# EVE2 register map
Vendor: Texas Instruments
Peripheral module from a debugger description file (folder DRA75x_DRA74x).
Registers are 32-bit, read-write, reset 0x0 unless marked. A register's access mark holds for its fields unless they carry their own. Offsets are as the file gives them; lines under a group give offsets from that group; [hi:lo] are bit positions; {n}, {i} and the like mark numbered series; 'fields as' and 'values as' point back to an identical list; <NAME> marks a mode.

## EVE2
0x80000 EVE_REVISION ro
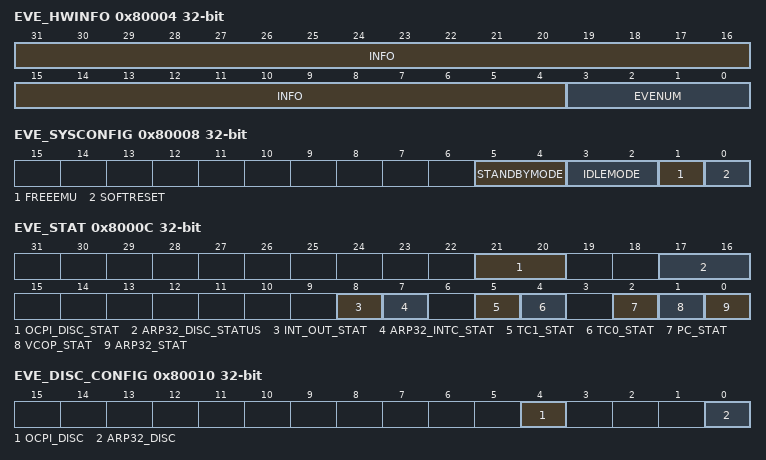
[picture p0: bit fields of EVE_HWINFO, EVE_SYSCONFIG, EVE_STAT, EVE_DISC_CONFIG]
0x80004 EVE_HWINFO ro
  [31:4] INFO — 0x0: No configurable options in EVE
  [3:0] EVENUM — EVE instance number set by eve_num inputs. In a multi-EVE system must be set to unique/incrementing values for each EVE.
0x80008 EVE_SYSCONFIG access per field
  [5:4] STANDBYMODE rw — 00: Force-Standby mode: This mode is a backup mode intended to be used only if the smart-idle mode is bugged. When in this mode / the SAF asserts with minimal hardware condition the status saying :I am in standby:. It is the responsibility of the software to ensure that the SAF is in a correct quiet state before programming this mode. Additionally when in this mode / the SAF is not allowed to generate wakeup reques . 01: No-Standby: This mode is a backup mode intended to be used only if the smart-idle mode is bugged. When in this mode / the SAF never asserts the status declaring that the system is in standby. 10: Smart-Standby: default. EVE generates the standby status based upon all hardware internal status / namely after having performed all hardware operations necessary to be in a correct quiet state. Additionally when in this mode / the SAF is not allowed to generate wakeup request. 11: Smart-Standby-Wkup: Same as Smart-Standby. (EVE generates the standby status based upon all hardware internal status / namely after having performed all hardware operations necessary to be in a correct quiet state ). . Additionally when in this mode / the SAF is allowed to generate wakeup request
  [3:2] IDLEMODE rw — 00: Force-idle: This mode is a backup mode intended to be used only if the smart-idle mode is bugged. When in this mode the IAF acknowledges a request to go idle from the power manager with minimal hardware condition. It is the responsibility of the software to ensure that the IAF are in a correct quiet state before requesting a force-idle transition. Additionaly when in this mode the IAF is not allowed to generate any wakeup request. 01: No-idle: When in this mode the IAF disregards any request to go idle from the power manager. 10: Smart-idle: default mode. default. When in this mode / the IAF acknowledges a request to go idle from the power manager after having performed all hardware operations necessary to be in a correct quiet state. Additionally when in this mode / the IAF is not allowed to generate any wakeup reques 11: SmartIdleWkup : When in this mode / the IAF acknowledges a request to go idle from the power manager after having performed all hardware operations necessary for the IAF to be in a correct quiet state. Additionally when in this mode / the IAF is allowed to generate wakeup request
  [1] FREEEMU ro — Resered. Note that SCTM has free control bit to define the timer operation during ARP32 debug halt mode
  [0] SOFTRESET ro — Reserved
0x8000C EVE_STAT ro — Added missing bit-field descriptions and settings to EVE_STAT register. See delta between vAB and vAC for more details
  [21:20] OCPI_DISC_STAT — OCP Initiator(s) Disconnect status2:
    2=One or both initiators are active, no request to disconnect is pending; 1=One or both initiators are attempting to disconnect; 0=EVEs_OCP_initiators_are_disconnected
  [17:16] ARP32_DISC_STATUS — ARP32 Program/Data Bus Disconnect Status 2:
    2=ARP32_2 (ARP32 program and data busses are active, no request to disconnect is pending); 1=ARP32_1 (ARP32 program and data buses are attempting to disconnect); 0=ARP32_0 (ARP32 program and data buses are disconnected)
  [8] INT_OUT_STAT — Interrupt Output status:
    0=No_edabled_interrupts_pending; 1=Active (at least one enabled interrupt source is pending in the output reducer)
  [7] ARP32_INTC_STAT — Interrupt Controller Status:
    0=No_enabled_interrupts_pending; 1=ARP32_1 (Active (at least one enabled interrupt source is pending in the ARP32 interrupt controller))
  [5] TC1_STAT — Transfer Controller1 Status:
    0=Idle; 1=Active
  [4] TC0_STAT — Transfer Controller0 Status:
    0=Idle; 1=Active
  [2] PC_STAT — Program Cache Status:
    0=Idle; 1=CPU_1 (Active (Program cache is either performing prefetch/preload/invalidation, or is servicing a CPU program fetch request (hit or miss)).)
  [1] VCOP_STAT — VCOP Status :
    0=Idle; 1=VCOP_OCP_1 (Active (Program execution in progress. Based on inverse of vcop_done. Does not account for activity on VCOP OCP debug interface))
  [0] ARP32_STAT — Program Cache Status:
    0=Idle; 1=Active (based on inverse of arp32_stanby)
0x80010 EVE_DISC_CONFIG access per field — Color 0 noise threshold
  [4] OCPI_DISC rw — OCP Initiator Disconnect request:
    1=OCP_1 (request for OCP initiator to disconnect and mask write byte enable signals. Writing 0 has no effect); 0=OCPI_DISC_0_r (Disconnect not in progress of has completed. Read 1: Disconnect request in progress.)
  [0] ARP32_DISC rw — ARP32 Initiator Disconnect request.
    1=ARP32_1 (Request for ARP32 program and data buses to disconnect and mask write byte enable signals. Writing 0 has no effect.); 1=ARP32_DISC_1_r (disconnect request in progress. Read 0: disconnect not in progress or has completed.)
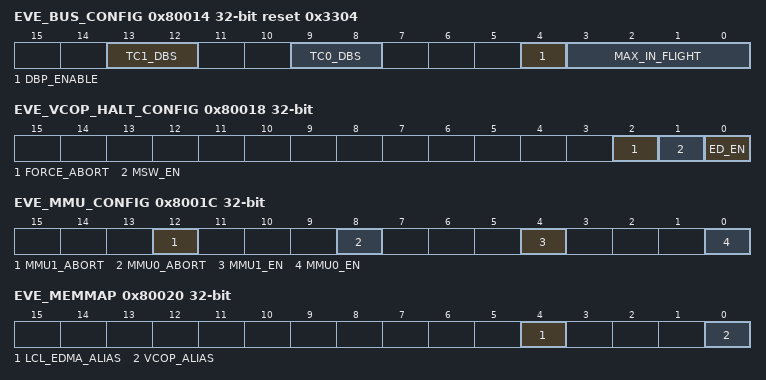
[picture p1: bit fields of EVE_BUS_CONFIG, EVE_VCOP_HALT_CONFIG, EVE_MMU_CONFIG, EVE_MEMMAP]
0x80014 EVE_BUS_CONFIG access per field reset 0x3304 — Color 0 noise threshold
  [13:12] TC1_DBS rw — TC1 default burst size. 00: 16 byte, 01: 32 byte, 10: 64 byte, 11: 128 byte (recommended)
  [9:8] TC0_DBS rw — TC0 default burst size. 00: 16 byte, 01: 32 byte, 10: 64 byte, 11: 128 byte (recommended)
  [4] DBP_ENABLE rw — Program Cache Demand Based Prefetch enable:
    0=DBP_disabled; 1=DBP_enabled
  [3:0] MAX_IN_FLIGHT rw — Defines maximum number of OCP requests in flight. Can be reduced to limit the peak bandwidth for software direct preload, which in turn may provide advantage to other EVE level (e.g. EDMA) or system-level initiators. 0: Reserved. 1: 1 request in flight allowed. 2: 2 requests in flight allowed.. F: 15 requests in flight allowed.
0x80018 EVE_VCOP_HALT_CONFIG access per field
  [2] FORCE_ABORT rw — VCOP Force Abort Write: Read always returns 0sWrite 0 has no effect. .
    1=VCOP_1 (issues force_abort command to VCOP (through pulse on vcop force abort input)
  [1] MSW_EN rw — VCOP Memory Seitch Error Halt Enable:
    0=Disabled; 1=VCOP_VCOP_1 (Enabled. VCOP halts on VCOP initiated memory swithc error)
  [0] ED_EN rw — VCOP Parity Error Detect Halt Enable:
    0=Disabled; 1=VCOP_VCOP_1 (Enabled. VCOP halts on VCOP initiated parity error.)
0x8001C EVE_MMU_CONFIG access per field
  [12] MMU1_ABORT rw — Causes the MMU to abort the current operation in case of lockup
  [8] MMU0_ABORT rw — Causes the MMU to abort the current operation in case of lockup
  [4] MMU1_EN rw — Clearing this bit disables MMU table lookup and causes accesses to use the non-translated address. This bit defaults to enabled but an identical bit within an MMU configuration register defaults to disabled and must be set after the page tables are programmed for MMU operation
  [0] MMU0_EN rw — Clearing this bit disables MMU table lookup and causes accesses to use the non-translated address. This bit defaults to enabled but an identical bit within an MMU configuration register defaults to disabled and must be set after the page tables are programmed for MMU operation
0x80020 EVE_MEMMAP access per field
  [4] LCL_EDMA_ALIAS rw — 0: Local EDMA views full memory map
    1=VCOP_VCOP_IBUFLA_IBUFLB_IBUFHA_IBUFHB_IBUFLA_IBUFLB_IBUFHA_IBUFHB_1 (VCOP vies aliased memory map. In this mode VCOP views IBUFLA and IBUFLB at the same address and views IBUFHA and IBUFHB at the same address. In this mode only one of IBUFLA or IBUFLB and IBUFHA or IBUFHB can be owned by the system.Refer to Error: Reference source not found for full truth table. Software must poll for updated value to ensure mode change has taken effect.)
  [0] VCOP_ALIAS rw — 0: VCOP views full memory map
    1=VCOP_VCOP_IBUFLA_IBUFLB_IBUFHA_IBUFHB_IBUFLA_IBUFLB_VCOP;_IBUFHA_IBUFHB_VCOP._1 (VCOP views Aliased memory map. In this mode / VCOP views IBUFLA and IBUFLB at the same address / and views IBUFHA and IBUFHB at the same address. In this mode / only one of IBUFLA or IBUFLB can be :owned: by VCOP; and only one of IBUFHA or IBUFHB can be :owned: by VCOP. Refer to Error: Reference source not found for full truth table. Software must poll for updated value to ensure mode change has taken effect)
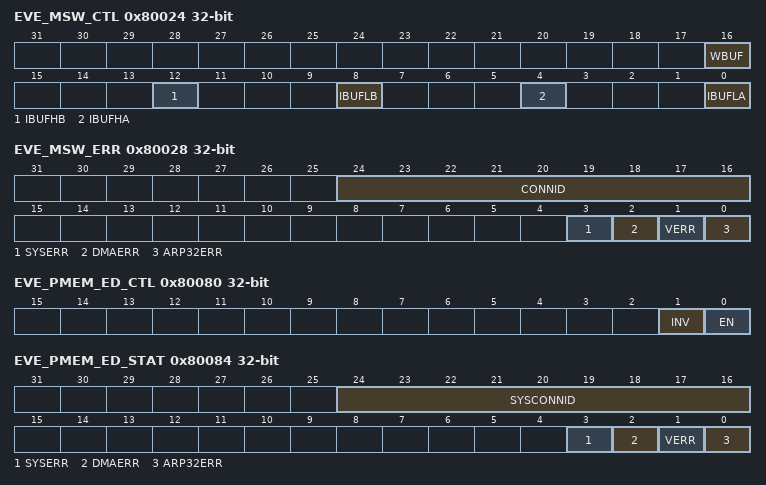
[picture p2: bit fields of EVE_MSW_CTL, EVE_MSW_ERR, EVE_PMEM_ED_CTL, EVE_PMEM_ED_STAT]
0x80024 EVE_MSW_CTL access per field — Memory switch control register
  [all] fields
    0=System_owned; 1=VCOP_owned
  [16] WBUF rw — Working buffer onwership. Value can be modified through direct writes to the memory mapped register address or through ARP32 executing custom instruction __SwitchBuffer(ucst20).
  [12] IBUFHB rw — Image buffer high B ownership. Value can be modified through direct writes to the memory mapped register address or through ARP32 executing custom instruction __SwitchBuffer(ucst20).:
  [8] IBUFLB rw — Image buffer low B ownership. Value can be modified through direct writes to the memory mapped register address or through ARP32 executing custom instruction __SwitchBuffer(ucst20).:
  [4] IBUFHA rw — Image buffer high A ownership. Value can be modified through direct writes to the memory mapped register address or through ARP32 executing custom instruction __SwitchBuffer(ucst20).:
  [0] IBUFLA rw — Image buffer low A ownership. Value can be modified through direct writes to the memory mapped register address or through ARP32 executing custom instruction __SwitchBuffer(ucst20).:
0x80028 EVE_MSW_ERR access per field — Memory Switch Error register
  [24:16] CONNID ro — Reads: OCP CONNID value for OCP request that results in buffer ownership error. CONNID[8] = 0 indicates system initiated request. CONNID[8] = 1 indicates internally initiated request. Valid only when SYSERR is set to 1 otherwise returns 0x0. Undefined when no error status bits are set. CONNID = 0x000 through 0x0FF / system initiator CONNID = 0x100 / ARP32 initiated error CONNID = 0x101 / VCOP initiated error CONNID = 0x102 / EDMA TC0 initiated error CONNID = 0x103 / EDMA TC1 initiated error. Cleared through write :1: to ERR bit field
  [3] SYSERR wo — 0 - System initiated buffer ownership error not recorded 1 - System initiated buffer ownership error detected/recorded. Write 1 to clear.
  [2] DMAERR wo — 0 : EDMA initiated buffer ownership error not recorded 1 : EDMA buffer ownership error detected/recorded Write 1 to clear.
  [1] VERR wo — 0 : VCOP initiated buffer ownership error not recorded 1 : VCOP initiated buffer ownership error detected/recorded Write 1 to clear.
  [0] ARP32ERR wo — 0 : ARP32 initiated buffer ownership error not recorded 1 : ARP32 initiated buffer ownership error detected/recorded Write 1 to clear.
0x8002C EVE_MSW_ERRADDR ro — Memory switch error address register
  [31:0] ADDR — Physical Address (i.e. / not aliased address) of memory switch error. For VCOP accesses / indicates 32-B aligned address. For EDMA or System accesses / indicates 16-B aligned access. For ARP32 / indicates 4-B aligned address. Value is undefined when no ERR bits set.
0x80040 EVE_PC_INV access per field — Invalidate all register
  [0] I rw — Invalidate all:Read: 0 : Invalidate operation complete / or not in progress 1 : Invalidate operation still in progress .
    0=I_0_w (no effet. Write 1: initiate invalidate all command)
0x80050 EVE_PC_IBAR — Invalidate Base Address register
  [31:0] ADDR — Invalidate Base Address register. Defines system byte address base to be invalidated from L1P. The entire range to be invalidated is (loosely speaking) from the base address to the base address + byte count. The actual range is inclusive of cache line (32-B aligned) addresses containing the start address and end address
0x80054 EVE_PC_IBC access per field — Invalidate byte count register
  [15:0] BC rw — Invalidate Byte Count register. Defines number of bytes relative to Invalidate Base Address (IBAR.ADDR) to be invalidated from L1P. Maximum of 32k (0x8000). Reads return 0x0 when invalidate range operation is complete.
0x80058 EVE_PC_ISAR — Invalidate single address register
  [31:0] ADDR — Invalidate Single Address register. Defines system byte address (1 line only) to be invalidated from L1P. Reads return 0x0 when the invalidate operation is complete.
0x8005C EVE_PC_ISAR_DONE ro — Invalidate single address done register
  [0] DONE — Reads return 0x1 when the invalidate operation is complete. Cleared on the next write to theEVE_PC_ISAR register
0x80060 EVE_PC_PBAR — Program cache preload base address register
  [31:0] ADDR — Preload Base Address register. Defines system byte address base to be Preloaded into L1P. The entire range to be Preloaded is (loosely speaking) from the base address to the base address + byte count. The actual range is inclusive of cache line (32-B aligned) addresses containing the start address and end address
0x80064 EVE_PC_PBC access per field
  [15:0] BC rw — Preload Byte Count register. Defines number of bytes relative to Preload Base Address (PBAR.ADDR) to be Preloaded into L1P. Maximum of 32k (0x8000). Reads return 0x0 when Preload range operation is complete
0x80080 EVE_PMEM_ED_CTL access per field — Program Memory Error Detection Control register
  [1] INV rw — Read 0: Error detection logic is not inverted. Read 1: Error detection logic is inverted. Writes to memory set parity as normal. Reds from meory return inverse of parity bit.Write 0 to clear, write 1 to set. Must be set when EN is set .
  [0] EN rw — Error detection logic enable. Writes update parity, reads check parity
    0=Disabled; 1=Enabled
0x80084 EVE_PMEM_ED_STAT access per field — Error detection status register
  [24:16] SYSCONNID rw — Reads: OCP CONNID value for OCP request that results in buffer ownership error. CONNID[8] = 0 indicates system initiated request. CONNID[8] = 1 indicates internally initiated request. Valid only when SYSERR is set to 1 otherwise returns 0x0. CONNID = 0x000 through 0x0FF / system initiator CONNID = 0x100 / ARP32 initiated error CONNID = 0x101 / VCOP initiated error CONNID = 0x102 / EDMA TC0 initiated error CONNID = 0x103 / EDMA TC1 initiated error. Cleared through write :1: to *ERR bit field.
  [3] SYSERR rw — 0 - System initiated parity error not recorded 1 - System initiated parity error detected/recorded. Write 1 to clear.
  [2] DMAERR rw — 0 : EDMA initiated parity error not recorded 1 : EDMA parity error detected/recorded Write 1 to clear.
  [1] VERR rw — 0 : VCOP initiated parity error not recorded 1 : VCOP initiated parity error detected/recorded Write 1 to clear.
  [0] ARP32ERR rw — 0 : ARP32 initiated parity error not recorded 1 : ARP32 initiated parity error detected/recorded Write 1 to clear
0x80088 EVE_PMEM_EDADDR ro — Program memory error detection address
  [31:0] ADDR — Physical Address (i.e. / not aliased address) of parity error. For VCOP accesses / indicates 32-B aligned address. For EDMA or System accesses / indicates 16-B aligned access. For ARP32 / indicates 4-B aligned address.
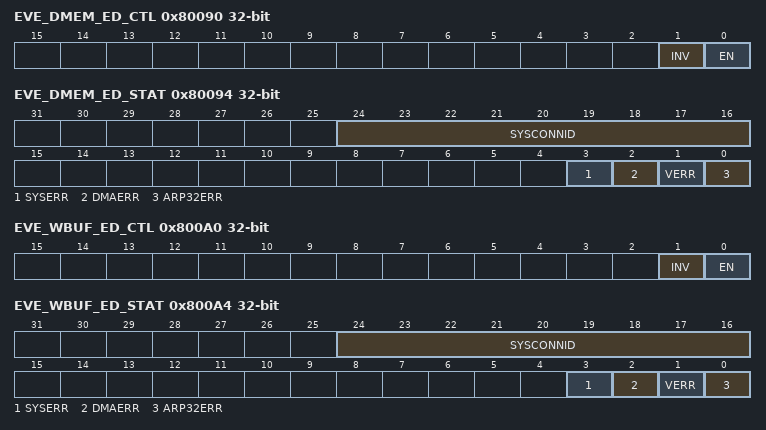
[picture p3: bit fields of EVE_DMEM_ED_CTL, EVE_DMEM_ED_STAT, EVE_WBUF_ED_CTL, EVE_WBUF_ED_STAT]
0x80090 EVE_DMEM_ED_CTL access per field — DMEM error detection control
  [1] INV rw — Read 0: Error detection logic is not inverted. Read 1: Error detection logic is inverted. Writes to memory set parity as normal. Reads from meory return inverse of parity bit.Write 0 to clear, write 1 to set. Must be set when EN is set .
  [0] EN rw — Error detection logic enable. Writes update parity, reads check parity
    0=Disabled; 1=Enabled
0x80094 EVE_DMEM_ED_STAT access per field — DMEM error detection status register
  fields as EVE_PMEM_ED_STAT
0x80098 EVE_DMEM_EDADDR ro — DMEM error detection address register
  fields as EVE_PMEM_EDADDR
0x8009C EVE_DMEM_EDADDR_BO ro — DMEM error detection address byte offset register
  [31:0] BO — Address byte offset for parity error. Indicates that an error has occured in byte offset #n. 0: No error occuredin byte offset #n; 1: Error occured in byte offset #n. Write to clear any of MEM.SYSERR/DMARR/ARP32/or VERR.
0x800A0 EVE_WBUF_ED_CTL access per field — WBUF error detection control
  [1] INV rw — Read 0: Error detection logic is not inverted. Read 1: Error detection logic is inverted. Writes to memory set parity as normal. Reads from meory return inverse of parity bit.Write 0 to clea Write 1 to set. Must be set when EN is set .
  [0] EN rw — Error detection logic enable. Writes update parity, reads check parity
    0=Disabled; 1=Enabled
0x800A4 EVE_WBUF_ED_STAT access per field — WBUF error detection status register
  fields as EVE_PMEM_ED_STAT
0x800A8 EVE_WBUF_EDADDR ro — WBUF error detection address register
  fields as EVE_PMEM_EDADDR
0x800AC EVE_WBUF_EDADDR_BO ro — WBUF error detection address byte offset register
  fields as EVE_DMEM_EDADDR_BO
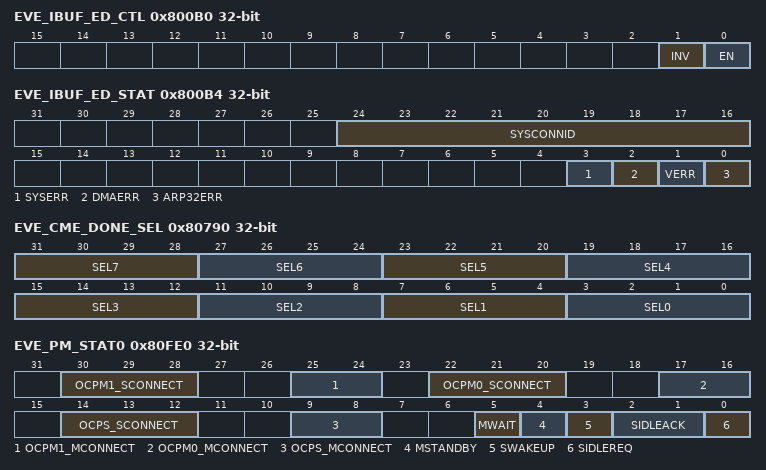
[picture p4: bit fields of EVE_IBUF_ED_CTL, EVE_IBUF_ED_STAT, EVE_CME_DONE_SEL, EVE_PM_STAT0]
0x800B0 EVE_IBUF_ED_CTL access per field — IBUF error detection control
  fields as EVE_DMEM_ED_CTL
0x800B4 EVE_IBUF_ED_STAT access per field — IBUF error detection status register
  fields as EVE_PMEM_ED_STAT
0x800B8 EVE_IBUF_EDADDR ro — IBUF error detection address register
  fields as EVE_PMEM_EDADDR
0x800BC EVE_IBUF_EDADDR_BO ro — IBUF error detection address byte offset register
  fields as EVE_DMEM_EDADDR_BO
0x800F8 EVE_ED_ARP32_DISC_EN access per field — ARP32 disconnect enable register
  [15:0] ENABLE rw — Disconnect Enable for Event #n 0: Disconnect disabled 1: Disconnect enabled
0x800FC EVE_ED_OCPI_DISC_EN access per field — OCP interface disconnect enable register
  [15:0] ENABLE rw — Disconnect Enable for Event #n. 0: Disconnect disabled 1: Disconnect enabled
0x80110 EVE_MSW_ERR_IRQSTATUS_RAW access per field — Per event memory switch error interrupt status register.
  [3:0] EVENT rw — settable raw status for event #n Write 0: No action Read 0: No event pending Read 1: Event pending Write 1: Set event (for debug)
0x80114 EVE_MSW_ERR_IRQSTATUS access per field — Memory switch error interrupt status register.
  [3:0] EVENT rw — Clearable / enabled status for event #N Write 0: No action Read 0: No (enabled) event pending Read 1: Enabled Event pending Write 1: Clear raw event
0x80118 EVE_MSW_ERR_IRQENABLE_SET access per field — Memory switch error interrupt enable register.
  [3:0] ENABLE rw — Enable for event #n Write 0: No action Read 0: Interrupt disabled Read 1: Interrupt enabled Write 1: Enable interrupt
0x8011C EVE_MSW_ERR_IRQENABLE_CLR access per field — Memory switch error interrupt clear register.
  [3:0] ENABLE rw — Enable for event #n Write 0: No action Read 0: Interrupt disabled Read 1: Interrupt enabled Write 1: Disable interrupt (i.e. / clear ENABLEn bit)
0x80120 EVE_ED_LCL_IRQSTATUS_RAW access per field — Per event error detection local interrupt status register.
  [15:0] EVENT rw — settable raw status for event #n Write 0: No action Read 0: No event pending Read 1: Event pending Write 1: Set event (for debug)
0x80124 EVE_ED_LCL_IRQSTATUS access per field — Error detection local interrupt status register.
  [15:0] EVENT rw — Clearable / enabled status for event #N Write 0: No action Read 0: No (enabled) event pending Read 1: Enabled Event pending Write 1: Clear raw event
0x80128 EVE_ED_LCL_IRQENABLE_SET access per field — Error detection local interrupt enable register.
  [15:0] ENABLE rw — Enable for event #n Write 0: No action Read 0: Interrupt disabled Read 1: Interrupt enabled Write 1: Enable interrupt
0x8012C EVE_ED_LCL_IRQENABLE_CLR access per field — Error detection local interrupt clear register.
  [15:0] ENABLE rw — Enable for event #n Write 0: No action Read 0: Interrupt disabled Read 1: Interrupt enabled Write 1: Disable interrupt (i.e. / clear ENABLEn bit)
0x80200 ARP32_NMI_IRQSTATUS_RAW
  [31:0] EVENT — settable raw status for event #n Write 0: No action Read 0: No event pending Read 1: Event pending Write 1: Set event (for debug)
0x80204 ARP32_NMI_IRQSTATUS
  [31:0] EVENT — Clearable / enabled status for event #N Write 0: No action Read 0: No (enabled) event pending Read 1: Enabled Event pending Write 1: Clear raw event
0x80208 ARP32_NMI_IRQENABLE_SET
  [31:0] ENABLE — Enable for event #n Write 0: No action Read 0: Interrupt disabled Read 1: Interrupt enabled Write 1: Enable interrupt
0x8020C ARP32_NMI_IRQENABLE_CLR
  [31:0] ENABLE — Enable for event #n Write 0: No action Read 0: Interrupt disabled Read 1: Interrupt enabled Write 1: Disable interrupt (i.e. / clear ENABLEn bit)
{0x801D0+0x10*i} ARP32_INTn_IRQSTATUS_RAW_{i} (i=4..7)
  fields as ARP32_NMI_IRQSTATUS_RAW
{0x801D4+0x10*i} ARP32_INTn_IRQSTATUS_{i} (i=4..7)
  fields as ARP32_NMI_IRQSTATUS
{0x801D8+0x10*i} ARP32_INTn_IRQENABLE_SET_{i} (i=4..7)
  fields as ARP32_NMI_IRQENABLE_SET
{0x801DC+0x10*i} ARP32_INTn_IRQENABLE_CLR_{i} (i=4..7)
  fields as ARP32_NMI_IRQENABLE_CLR
0x802FC ARP32_IRQWAKEEN access per field — Wake enable register
  [23:0] ENABLE rw — Wakeup Enable for event EVE_EVT_INT #n 0: Interrupt #n disabled for wakeup 1: Interrupt #n enabled for wakeup
{0x80300+4i} MMR_LOCKi_{i} (i=0..9) — MMR Lock/Unlock register
  [31:0] MMR_LOCK — Lock/Unlock register for corresponding region
0x80400 MISR_CTL access not given
  [2:0] ENABLE rw — MISR Enable #N 0: MISR #n disabled 1: MISR #n enabled Bit 0: MISR 0 - ARP32 PMEM path Bit 1: MISR 1 - ARP32 DMEM path Bit 2: MISR 2 - INTC WBUF path
0x80404 MISR_CLEAR access per field
  [2:0] CLEAR rw — MISR Clear #N Write 0: no effect Write 1: Clear MISR #n Read 0: Previous MISR clear command has completed. Read 1: MISR Clear in progress (this state may never actually be readable)
0x80410 MISR0_A
  [31:0] SIGNATURE — MISR Signature Value Write value to initialize to a desired seed. (only valid when disabled / undefined when enabled). Must be written as a 32-b write w/ all byte enable signals active. Read value returns current signature value.
0x80414 MISR0_D
  fields as MISR0_A
0x80418 MISR1_A
  fields as MISR0_A
0x8041C MISR1_D
  fields as MISR0_A
{0x80420+4i} MISR2_Dk_{i} (i=0..3)
  fields as MISR0_A
0x80500 EVE_IRQ_EOI access per field
  [2:0] LINE_NUMBER rw — Software End Of Interrupt (EOI) control. Write number of interrupt output to force re-evaluation of associated pending interrupts. Refer to Section Error: Reference source not found for EOI mapping. Reads always return 0x0. Write n : EOI for Interrupt output associated w/ EOI #n.
0x80510 EVE_ED_OUT_IRQSTATUS_RAW access per field
  [15:0] EVENT rw — Settable raw status for event #n Write 0: No action Read 0: No event pending Read 1: Event pending Write 1: Set event (for debug)
0x80514 EVE_ED_OUT_IRQSTATUS access per field
  fields as EVE_ED_LCL_IRQSTATUS
0x80518 EVE_ED_OUT_IRQENABLE_SET access per field
  fields as EVE_ED_LCL_IRQENABLE_SET
0x8051C EVE_ED_OUT_IRQENABLE_CLR access per field
  fields as EVE_ED_LCL_IRQENABLE_CLR
{0x80520+0x10*i} EVE_INTk_OUT_IRQSTATUS_RAW_{i} (i=0..3)
  fields as ARP32_NMI_IRQSTATUS_RAW
{0x80524+0x10*i} EVE_INTk_OUT_IRQSTATUS_{i} (i=0..3)
  [31:0] EVENT — Clearable / enabled status for event #N Write 0: No action Read 0: No (enabled) event pending Read 1: Enabled Event pending Write 1: Clear raw event.
{0x80528+0x10*i} EVE_INTk_OUT_IRQENABLE_SET_{i} (i=0..3)
  fields as ARP32_NMI_IRQENABLE_SET
{0x8052C+0x10*i} EVE_INTk_OUT_IRQENABLE_CLR_{i} (i=0..3)
  fields as ARP32_NMI_IRQENABLE_CLR
{0x80580+0x10*i} ARP32_INTj_IRQSTATUS_RAW_{i} ro (i=8..13)
  fields as ARP32_NMI_IRQSTATUS_RAW
{0x80584+0x10*i} ARP32_INTj_IRQSTATUS_{i} (i=8..13)
  fields as ARP32_NMI_IRQSTATUS
{0x80588+0x10*i} ARP32_INTj_IRQENABLE_SET_{i} (i=8..13)
  fields as ARP32_NMI_IRQENABLE_SET
{0x8058C+0x10*i} ARP32_INTj_IRQENABLE_CLR_{i} (i=8..13)
  fields as ARP32_NMI_IRQENABLE_CLR
0x80680 ARP32_INT14_IRQSTATUS_RAW ro
  fields as ARP32_NMI_IRQSTATUS_RAW
0x80684 ARP32_INT14_IRQSTATUS
  fields as ARP32_NMI_IRQSTATUS
0x80688 ARP32_INT14_IRQENABLE_SET
  fields as ARP32_NMI_IRQENABLE_SET
0x8068C ARP32_INT14_IRQENABLE_CLR
  fields as ARP32_NMI_IRQENABLE_CLR
0x80690 ARP32_INT15_IRQSTATUS_RAW ro
  fields as ARP32_NMI_IRQSTATUS_RAW
0x80694 ARP32_INT15_IRQSTATUS
  fields as ARP32_NMI_IRQSTATUS
0x80698 ARP32_INT15_IRQENABLE_SET
  fields as ARP32_NMI_IRQENABLE_SET
0x8069C ARP32_INT15_IRQENABLE_CLR
  fields as ARP32_NMI_IRQENABLE_CLR
0x80700 EVE_GPOUTm_0
  [31:0] EVENT — GP Output #n Write 0: Drive GP Output #n low/1 Read 0: GP Output #n is low/0. Write 1: Drive GP Output #n high/1. Read 1: GP Output is high/1.
0x80704 EVE_GPOUTm_SET_0
  [31:0] EVENT — GP Output #n Write 0: No action Read 0: GP Output #n is low/0. Write 1: Drive GP Output #n high/1. Read 1: GP Output is high/1.
0x80708 EVE_GPOUTm_CLR_0
  fields as EVE_GPOUTm_0
0x8070C EVE_GPOUTm_PULSE_0
  [31:0] EVENT — GP Output #n Write 0: No action Read 0: GP Output #n is low/0. Write 1: Drive GP Output #n high/1 for four cycles / then drive low/0. Read 1: GP Output #n is high/1. Note: Writing to GPOUT registers when the four cycles for the previous write to GPOUT_PULSE register have not been completed can result in unpredictable output.
0x80710 EVE_GPOUTm_1
  fields as EVE_GPOUTm_0
0x80714 EVE_GPOUTm_SET_1
  fields as EVE_GPOUTm_SET_0
0x80718 EVE_GPOUTm_CLR_1
  fields as EVE_GPOUTm_0
0x8071C EVE_GPOUTm_PULSE_1
  fields as EVE_GPOUTm_PULSE_0
0x80740 EVE_GPIN0 ro
  [31:0] EVENT — GP Input #n Read 0: GP Input #n is low/0. Read 1: GP Input is high/1.
0x80744 EVE_GPIN1 ro
  fields as EVE_GPIN0
0x80780 EVE_CME_DONE_GPOUT access per field
  [7:0] EVENT rw — Internal CME Done Output #n. Write 0: Drive Internal CME Done #n low/1 Read 0: Drive Internal CME Done #n is low/0. Write 1: Drive Internal CME Done #n high/1. Read 1: Internal CME Done is high/1.
0x80784 EVE_CME_DONE_GPOUT_SET access per field
  [7:0] EVENT rw — Internal CME Done #n Write 0: No action Read 0: Internal CME Done #n is low/0. Write 1: Drive Internal CME Done #n high/1. Read 1: Internal CME Done is high/1.
0x80788 EVE_CME_DONE_GPOUT_CLR access per field
  [7:0] EVENT rw — Internal CME Done #n Write 0: No action Read 0: Internal CME Done #n is low/0. Write 1: Drive Internal CME Done #n low/0. Read 1: Internal CME Done #n is high/1.
0x8078C EVE_CME_DONE_GPOUT_PULSE access per field
  [7:0] EVENT rw — Internal CME Done #n Write 0: No action Read 0: Internal CME Done #n is low/0. Write 1: Drive Internal CME Done #n high/1 for four cycles / then drive low/0. Read 1: Internal CME Done #n is high/1. Note: Writing to GPOUT registers when the four cycles for the previous write to GPOUT_PULSE register have not been completed can result in unpredictable output.
0x80790 EVE_CME_DONE_SEL
  [31:28] SEL7 — CME Done Output select for Bit #7 (n=7) .
  [27:24] SEL6 — CME Done Output select for Bit #6 (n=6) .
  [23:20] SEL5 — CME Done Output select for Bit #5 (n=5).
  [19:16] SEL4 — CME Done Output select for Bit #4 (n=4) .
  [15:12] SEL3 — CME Done Output select for Bit #3 (n=3) .
  [11:8] SEL2 — CME Done Output select for Bit #2 (n=2) .
  [7:4] SEL1 — CME Done Output select for Bit #1 (n=1) .
  [3:0] SEL0 — CME Done Output select for Bit #0 (n=0) 0: Driven by EDMA cc_int0 1: Driven by EDMA cc_int1 2: Driven by EDMA cc_int2 3: Driven by EDMA cc_int3 4: Driven by EDMA cc_int4 5: Driven by EDMA cc_int5 6: Driven by EDMA cc_int6 7: Driven by EDMA cc_int7 8: Driven by EVE_CME_DONE_GPOUTn 9: driven by eve_cme_done_gpout[0+n] (from EVE1) 10: driven by eve_cme_done_gpout[8+n] (from EVE2) 11: driven by eve_cme_done_gpout[16+n] (from EVE3) 12: driven by eve_cme_done_gpout[24+n] (from EVE4) 13: driven by eve_cme_done_gpout[32+n] (from EVE5) 14: driven by eve_cme_done_gpout[40+n] (from EVE6) 15: driven by eve_cme_done_gpout[48+n] (from EVE7)
0x80794 EVE_CME_DONE_EN access per field
  [7:0] EN rw — EVE CME Done EN #n Write 0: No action Read 0: EVE CME Done #n is disabled. Write 1: Enable EVE CME Done #n event. This allows the status of the CME Done #n to propagate to the output. Read 1: EVE CME Done #n is enabled.
0x80FE0 EVE_PM_STAT0 ro
  [30:28] OCPM1_SCONNECT — Readable state of OCP Power management handshake
  [25:24] OCPM1_MCONNECT — Readable state of OCP Power management handshake
  [22:20] OCPM0_SCONNECT — Readable state of OCP Power management handshake
  [17:16] OCPM0_MCONNECT — Readable state of OCP Power management handshake
  [14:12] OCPS_SCONNECT — Readable state of OCP Power management handshake
  [9:8] OCPS_MCONNECT — Readable state of OCP Power management handshake
  [5] MWAIT — Readable state of OCP Power management handshake
  [4] MSTANDBY — Readable state of OCP Power management handshake
  [3] SWAKEUP — Readable state of OCP Power management handshake
  [2:1] SIDLEACK — Readable state of OCP Power management handshake
  [0] SIDLEREQ — Readable state of OCP Power management handshake
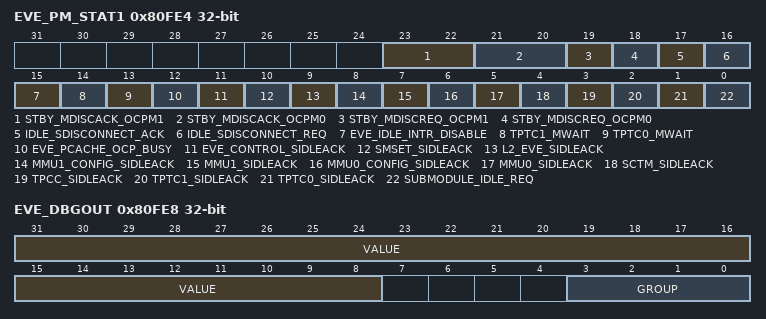
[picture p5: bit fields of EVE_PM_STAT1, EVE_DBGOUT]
0x80FE4 EVE_PM_STAT1 access not given (reset mask 0xFFFFFFFE)
  [23:22] STBY_MDISCACK_OCPM1 ro — Readable state of internal power management handshake
  [21:20] STBY_MDISCACK_OCPM0 ro — Readable state of internal power management handshake
  [19] STBY_MDISCREQ_OCPM1 ro — Readable state of internal power management handshake
  [18] STBY_MDISCREQ_OCPM0 ro — Readable state of internal power management handshake
  [17] IDLE_SDISCONNECT_ACK ro — Readable state of internal power management handshake
  [16] IDLE_SDISCONNECT_REQ ro — Readable state of internal power management handshake
  [15] EVE_IDLE_INTR_DISABLE ro — Readable state of internal power management handshake
  [14] TPTC1_MWAIT ro — Readable state of internal power management handshake
  [13] TPTC0_MWAIT ro — Readable state of internal power management handshake
  [12] EVE_PCACHE_OCP_BUSY ro — Readable state of internal power management handshake
  [11] EVE_CONTROL_SIDLEACK ro — Readable state of internal power management handshake
  [10] SMSET_SIDLEACK ro — Readable state of internal power management handshake
  [9] L2_EVE_SIDLEACK ro — Readable state of internal power management handshake
  [8] MMU1_CONFIG_SIDLEACK ro — Readable state of internal power management handshake
  [7] MMU1_SIDLEACK ro — Readable state of internal power management handshake
  [6] MMU0_CONFIG_SIDLEACK ro — Readable state of internal power management handshake
  [5] MMU0_SIDLEACK ro — Readable state of internal power management handshake
  [4] SCTM_SIDLEACK ro — Readable state of internal power management handshake
  [3] TPCC_SIDLEACK ro — Readable state of internal power management handshake
  [2] TPTC1_SIDLEACK ro — Readable state of internal power management handshake
  [1] TPTC0_SIDLEACK ro — Readable state of internal power management handshake
  [0] SUBMODULE_IDLE_REQ
0x80FE8 EVE_DBGOUT access per field
  [31:8] VALUE ro — Read returns state of eve_dbgout bus.
  [3:0] GROUP rw — Debug Group Output control : mux select 0x0 : disabled / all debug outputs driven to 0x0. 0x1 : select output group1 0x2 : select output group2 : 0xN : select output groupN Others - reserved
0x80FF4 EVE_RSVD0
  [31:0] VAL — Value; This register is reserved for any necessary ECOs that may be required later in the design cycle.
0x80FF8 EVE_RSVD1
  fields as EVE_RSVD0
0x80FFC EVE_TEST
  fields as EVE_RSVD0
